# ATSAMD21G17L register map
Vendor: Microchip Technology Inc.; File version: G
CPU: CM0+ r0p1, little endian, no MPU, no FPU, 0x2 interrupt priority bits, 0x0 interrupts
Registers are 32-bit, read-write, reset 0x0 unless marked. A register's access mark holds for its fields unless they carry their own. Offsets are from the block's base; [hi:lo] are bit positions; {n}, {i} and the like mark numbered series; 'fields as' and 'values as' point back to an identical list.

## TCC0 — Timer Counter Control 0
Base 0x42002000; register names take the prefix TCC_
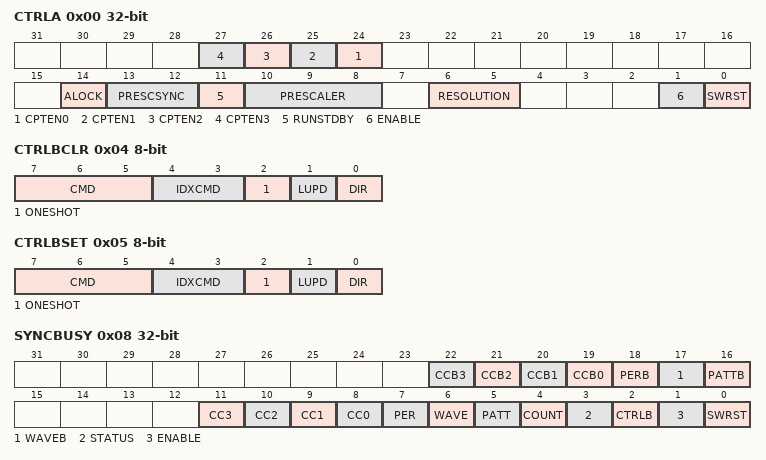
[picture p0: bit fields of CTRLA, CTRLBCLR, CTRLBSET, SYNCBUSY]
0x00 CTRLA — Control A
  [n+24] CPTEN{n} (n=0..3) — Capture Channel {n} Enable
  [14] ALOCK — Auto Lock
  [13:12] PRESCSYNC — Prescaler and Counter Synchronization Selection
    0=GCLK (Reload or reset counter on next GCLK); 1=PRESC (Reload or reset counter on next prescaler clock); 2=RESYNC (Reload or reset counter on next GCLK and reset prescaler counter)
  [11] RUNSTDBY — Run in Standby
  [10:8] PRESCALER
    0=DIV1 (No division); 1=DIV2 (Divide by 2); 2=DIV4 (Divide by 4); 3=DIV8 (Divide by 8); 4=DIV16 (Divide by 16); 5=DIV64 (Divide by 64); 6=DIV256 (Divide by 256); 7=DIV1024 (Divide by 1024)
  [6:5] RESOLUTION — Enhanced Resolution
    0=NONE (Dithering is disabled); 1=DITH4 (Dithering is done every 16 PWM frames); 2=DITH5 (Dithering is done every 32 PWM frames); 3=DITH6 (Dithering is done every 64 PWM frames)
  [1] ENABLE
  [0] SWRST — Software Reset
0x04 CTRLBCLR 8-bit — Control B Clear
  [7:5] CMD — TCC Command
    0=NONE (No action); 1=RETRIGGER (Clear start, restart or retrigger); 2=STOP (Force stop); 3=UPDATE (Force update of double buffered registers); 4=READSYNC (Force COUNT read synchronization)
  [4:3] IDXCMD — Ramp Index Command
    0=DISABLE (Command disabled: Index toggles between cycles A and B); 1=SET (Set index: cycle B will be forced in the next cycle); 2=CLEAR (Clear index: cycle A will be forced in the next cycle); 3=HOLD (Hold index: the next cycle will be the same as the current cycle)
  [2] ONESHOT
  [1] LUPD — Lock Update
  [0] DIR — Counter Direction
0x05 CTRLBSET 8-bit — Control B Set
  fields as CTRLBCLR
0x08 SYNCBUSY ro — Synchronization Busy
  [n+19] CCB{n} (n=0..3) — Compare Channel Buffer {n} Busy
  [18] PERB — Period Buffer Busy
  [17] WAVEB — Wave Buffer Busy
  [16] PATTB — Pattern Buffer Busy
  [n+8] CC{n} (n=0..3) — Compare Channel {n} Busy
  [7] PER — Period busy
  [6] WAVE — Wave Busy
  [5] PATT — Pattern Busy
  [4] COUNT — Count Busy
  [3] STATUS — Status Busy
  [2] CTRLB — Ctrlb Busy
  [1] ENABLE — Enable Busy
  [0] SWRST — Swrst Busy
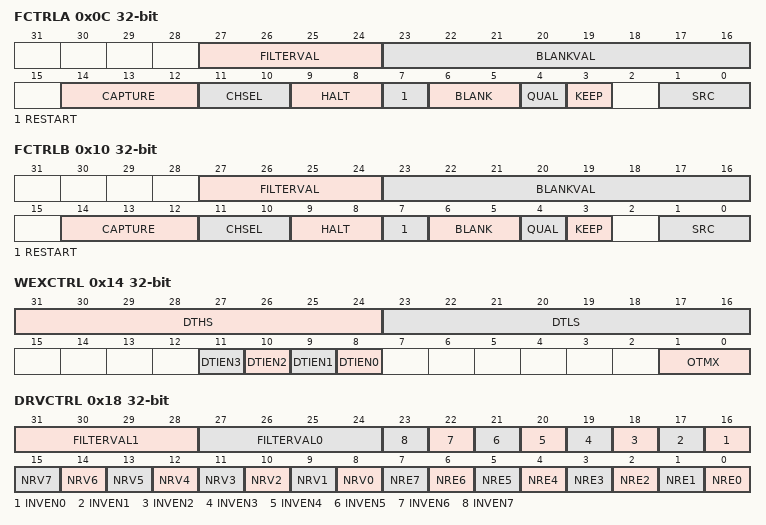
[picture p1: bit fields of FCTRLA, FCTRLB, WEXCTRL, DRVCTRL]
0x0C FCTRLA — Recoverable Fault A Configuration
  [27:24] FILTERVAL — Fault A Filter Value
  [23:16] BLANKVAL — Fault A Blanking Time
  [14:12] CAPTURE — Fault A Capture Action
    0=DISABLE (No capture); 1=CAPT (Capture on fault); 2=CAPTMIN (Minimum capture); 3=CAPTMAX (Maximum capture); 4=LOCMIN (Minimum local detection); 5=LOCMAX (Maximum local detection); 6=DERIV0 (Minimum and maximum local detection); 7=CAPTMARK (Capture with ramp index as MSB value)
  [11:10] CHSEL — Fault A Capture Channel
    {v}=CC{v} (Capture value stored in channel {v}) (v=0..3)
  [9:8] HALT — Fault A Halt Mode
    0=DISABLE (Halt action disabled); 1=HW (Hardware halt action); 2=SW (Software halt action); 3=NR (Non-recoverable fault)
  [7] RESTART — Fault A Restart
  [6:5] BLANK — Fault A Blanking Mode
    0=START (Blanking applied from start of ramp); 1=RISE (Blanking applied from rising edge of the output waveform); 2=FALL (Blanking applied from falling edge of the output waveform); 3=BOTH (Blanking applied from each toggle of the output waveform)
  [4] QUAL — Fault A Qualification
  [3] KEEP — Fault A Keeper
  [1:0] SRC — Fault A Source
    0=DISABLE (Fault input disabled); 1=ENABLE (MCEx (x=0,1) event input); 2=INVERT (Inverted MCEx (x=0,1) event input); 3=ALTFAULT (Alternate fault (A or B) state at the end of the previous period)
0x10 FCTRLB — Recoverable Fault B Configuration
  [27:24] FILTERVAL — Fault B Filter Value
  [23:16] BLANKVAL — Fault B Blanking Time
  [14:12] CAPTURE — Fault B Capture Action
    values as FCTRLA.CAPTURE
  [11:10] CHSEL — Fault B Capture Channel
    {v}=CC{v} (Capture value stored in channel {v}) (v=0..3)
  [9:8] HALT — Fault B Halt Mode
    values as FCTRLA.HALT
  [7] RESTART — Fault B Restart
  [6:5] BLANK — Fault B Blanking Mode
    values as FCTRLA.BLANK
  [4] QUAL — Fault B Qualification
  [3] KEEP — Fault B Keeper
  [1:0] SRC — Fault B Source
    values as FCTRLA.SRC
0x14 WEXCTRL — Waveform Extension Configuration
  [31:24] DTHS — Dead-time High Side Outputs Value
  [23:16] DTLS — Dead-time Low Side Outputs Value
  [n+8] DTIEN{n} (n=0..3) — Dead-time Insertion Generator {n} Enable
  [1:0] OTMX — Output Matrix
0x18 DRVCTRL — Driver Control
  [31:28] FILTERVAL1 — Non-Recoverable Fault Input 1 Filter Value
  [27:24] FILTERVAL0 — Non-Recoverable Fault Input 0 Filter Value
  [n+16] INVEN{n} (n=0..7) — Output Waveform {n} Inversion
  [n+8] NRV{n} (n=0..7) — Non-Recoverable State {n} Output Value
  [n] NRE{n} (n=0..7) — Non-Recoverable State {n} Output Enable
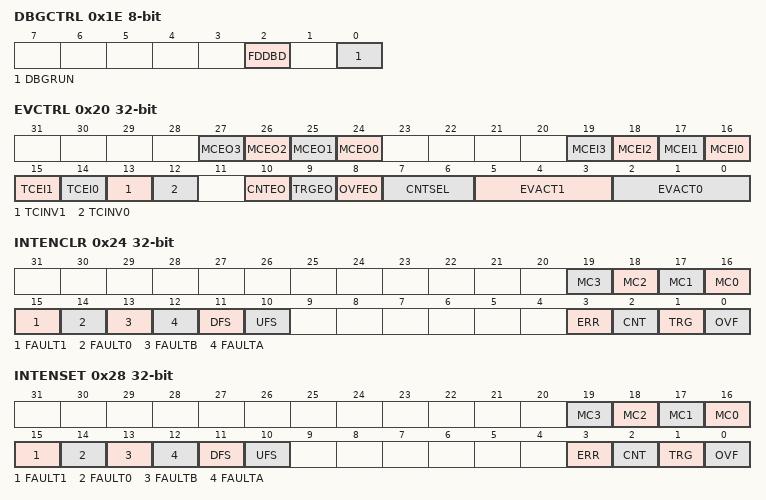
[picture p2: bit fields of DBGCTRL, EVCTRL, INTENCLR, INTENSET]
0x1E DBGCTRL 8-bit — Debug Control
  [2] FDDBD — Fault Detection on Debug Break Detection
  [0] DBGRUN — Debug Running Mode
0x20 EVCTRL — Event Control
  [n+24] MCEO{n} (n=0..3) — Match or Capture Channel {n} Event Output Enable
  [n+16] MCEI{n} (n=0..3) — Match or Capture Channel {n} Event Input Enable
  [15] TCEI1 — Timer/counter Event 1 Input Enable
  [14] TCEI0 — Timer/counter Event 0 Input Enable
  [13] TCINV1 — Inverted Event 1 Input Enable
  [12] TCINV0 — Inverted Event 0 Input Enable
  [10] CNTEO — Timer/counter Output Event Enable
  [9] TRGEO — Retrigger Output Event Enable
  [8] OVFEO — Overflow/Underflow Output Event Enable
  [7:6] CNTSEL — Timer/counter Output Event Mode
    0=START (An interrupt/event is generated when a new counter cycle starts); 1=END (An interrupt/event is generated when a counter cycle ends); 2=BETWEEN (An interrupt/event is generated when a counter cycle ends, except for the first and last cycles); 3=BOUNDARY (An interrupt/event is generated when a new counter cycle starts or a counter cycle ends)
  [5:3] EVACT1 — Timer/counter Input Event1 Action
    0=OFF (Event action disabled); 1=RETRIGGER (Re-trigger counter on event); 2=DIR (Direction control); 3=STOP (Stop counter on event); 4=DEC (Decrement counter on event); 5=PPW (Period capture value in CC0 register, pulse width capture value in CC1 register); 6=PWP (Period capture value in CC1 register, pulse width capture value in CC0 register); 7=FAULT (Non-recoverable fault)
  [2:0] EVACT0 — Timer/counter Input Event0 Action
    0=OFF (Event action disabled); 1=RETRIGGER (Start, restart or re-trigger counter on event); 2=COUNTEV (Count on event); 3=START (Start counter on event); 4=INC (Increment counter on event); 5=COUNT (Count on active state of asynchronous event); 6=STAMP (Stamp capture); 7=FAULT (Non-recoverable fault)
0x24 INTENCLR — Interrupt Enable Clear
  [n+16] MC{n} (n=0..3) — Match or Capture Channel {n} Interrupt Enable
  [15] FAULT1 — Non-Recoverable Fault 1 Interrupt Enable
  [14] FAULT0 — Non-Recoverable Fault 0 Interrupt Enable
  [13] FAULTB — Recoverable Fault B Interrupt Enable
  [12] FAULTA — Recoverable Fault A Interrupt Enable
  [11] DFS — Non-Recoverable Debug Fault Interrupt Enable
  [10] UFS — Non-Recoverable Update Fault Interrupt Enable
  [3] ERR — Error Interrupt Enable
  [2] CNT — Counter Interrupt Enable
  [1] TRG — Retrigger Interrupt Enable
  [0] OVF — Overflow Interrupt Enable
0x28 INTENSET — Interrupt Enable Set
  fields as INTENCLR
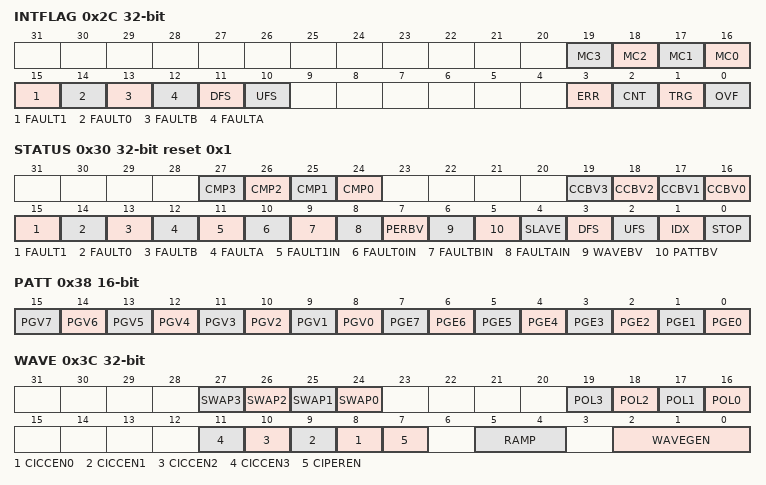
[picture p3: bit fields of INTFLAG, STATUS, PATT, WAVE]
0x2C INTFLAG — Interrupt Flag Status and Clear
  [n+16] MC{n} (n=0..3) — Match or Capture {n}
  [15] FAULT1 — Non-Recoverable Fault 1
  [14] FAULT0 — Non-Recoverable Fault 0
  [13] FAULTB — Recoverable Fault B
  [12] FAULTA — Recoverable Fault A
  [11] DFS — Non-Recoverable Debug Fault
  [10] UFS — Non-Recoverable Update Fault
  [3] ERR — Error
  [2] CNT — Counter
  [1] TRG — Retrigger
  [0] OVF — Overflow
0x30 STATUS reset 0x1
  [n+24] CMP{n} ro (n=0..3) — Compare Channel {n} Value
  [n+16] CCBV{n} (n=0..3) — Compare Channel {n} Buffer Valid
  [15] FAULT1 — Non-Recoverable Fault 1 State
  [14] FAULT0 — Non-Recoverable Fault 0 State
  [13] FAULTB — Recoverable Fault B State
  [12] FAULTA — Recoverable Fault A State
  [11] FAULT1IN ro — Non-Recoverable Fault1 Input
  [10] FAULT0IN ro — Non-Recoverable Fault0 Input
  [9] FAULTBIN ro — Recoverable Fault B Input
  [8] FAULTAIN ro — Recoverable Fault A Input
  [7] PERBV — Period Buffer Valid
  [6] WAVEBV — Wave Buffer Valid
  [5] PATTBV — Pattern Buffer Valid
  [4] SLAVE ro
  [3] DFS — Non-Recoverable Debug Fault State
  [2] UFS — Non-Recoverable Update Fault State
  [1] IDX ro — Ramp
  [0] STOP ro
0x34 COUNT
  [23:0] COUNT — Counter Value
0x34 COUNT_DITH{i} (i=4..6) — Count
  [23:{i}] COUNT — Counter Value
0x38 PATT 16-bit — Pattern
  [n+8] PGV{n} (n=0..7) — Pattern Generator {n} Output Value
  [n] PGE{n} (n=0..7) — Pattern Generator {n} Output Enable
0x3C WAVE — Waveform Control
  [n+24] SWAP{n} (n=0..3) — Swap DTI Output Pair {n}
  [n+16] POL{n} (n=0..3) — Channel {n} Polarity
  [n+8] CICCEN{n} (n=0..3) — Circular Channel {n} Enable
  [7] CIPEREN — Circular period Enable
  [5:4] RAMP — Ramp Mode
    0=RAMP1 operation; 1=RAMP2A (Alternative RAMP2 operation); 2=RAMP2 operation; 3=RAMP2C (Critical RAMP2 operation)
  [2:0] WAVEGEN — Waveform Generation
    0=NFRQ (Normal frequency); 1=MFRQ (Match frequency); 2=NPWM (Normal PWM); 4=DSCRITICAL (Dual-slope critical); 5=DSBOTTOM (Dual-slope with interrupt/event condition when COUNT reaches ZERO); 6=DSBOTH (Dual-slope with interrupt/event condition when COUNT reaches ZERO or TOP); 7=DSTOP (Dual-slope with interrupt/event condition when COUNT reaches TOP)
0x40 PER reset 0xFFFFFFFF — Period
  [23:0] PER — Period Value
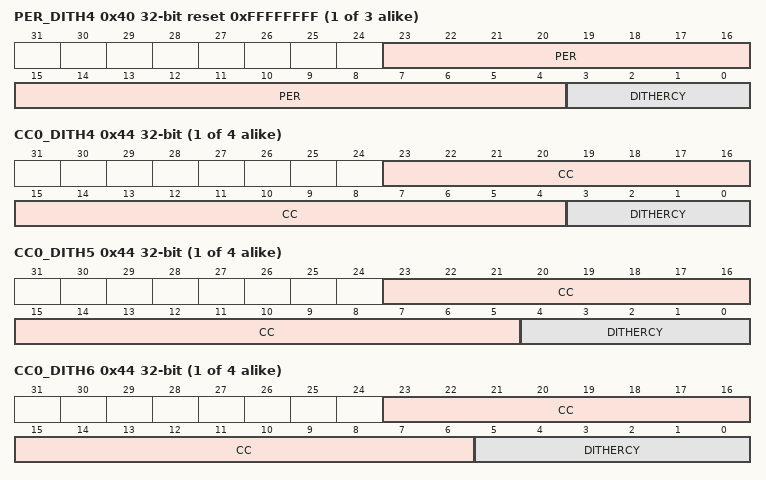
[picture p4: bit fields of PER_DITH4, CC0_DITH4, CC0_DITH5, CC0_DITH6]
0x40 PER_DITH{i} reset 0xFFFFFFFF (i=4..6) — Period
  [23:{i}] PER — Period Value
  [{i-1}:0] DITHERCY — Dithering Cycle Number
{0x44+4i} CC{i} (i=0..3) — Compare and Capture
  [23:0] CC — Channel Compare/Capture Value
{0x44+4i} CC{i}_DITH4 (i=0..3) — Compare and Capture
  [23:4] CC — Channel Compare/Capture Value
  [3:0] DITHERCY — Dithering Cycle Number
{0x44+4i} CC{i}_DITH5 (i=0..3) — Compare and Capture
  [23:5] CC — Channel Compare/Capture Value
  [4:0] DITHERCY — Dithering Cycle Number
{0x44+4i} CC{i}_DITH6 (i=0..3) — Compare and Capture
  [23:6] CC — Channel Compare/Capture Value
  [5:0] DITHERCY — Dithering Cycle Number
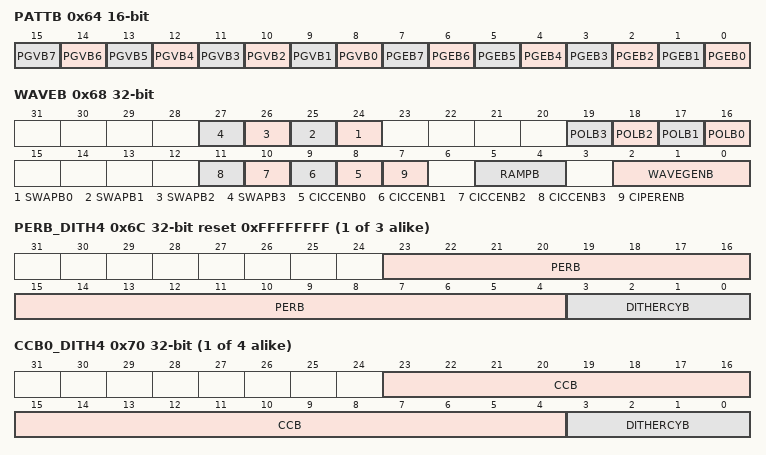
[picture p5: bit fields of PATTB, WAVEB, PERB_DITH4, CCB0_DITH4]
0x64 PATTB 16-bit — Pattern Buffer
  [n+8] PGVB{n} (n=0..7) — Pattern Generator {n} Output Enable
  [n] PGEB{n} (n=0..7) — Pattern Generator {n} Output Enable Buffer
0x68 WAVEB — Waveform Control Buffer
  [n+24] SWAPB{n} (n=0..3) — Swap DTI Output Pair {n} Buffer
  [n+16] POLB{n} (n=0..3) — Channel {n} Polarity Buffer
  [n+8] CICCENB{n} (n=0..3) — Circular Channel {n} Enable Buffer
  [7] CIPERENB — Circular Period Enable Buffer
  [5:4] RAMPB — Ramp Mode Buffer
    0=RAMP1 (RAMP1 operation); 1=RAMP2A (Alternative RAMP2 operation); 2=RAMP2 (RAMP2 operation); 3=RAMP2C (Critical RAMP2 operation)
  [2:0] WAVEGENB — Waveform Generation Buffer
    values as WAVE.WAVEGEN
0x6C PERB reset 0xFFFFFFFF — Period Buffer
  [23:0] PERB — Period Buffer Value
0x6C PERB_DITH{i} reset 0xFFFFFFFF (i=4..6) — Period Buffer
  [23:{i}] PERB — Period Buffer Value
  [{i-1}:0] DITHERCYB — Dithering Buffer Cycle Number
{0x70+4i} CCB{i} (i=0..3) — Compare and Capture Buffer
  [23:0] CCB — Channel Compare/Capture Buffer Value
{0x70+4i} CCB{i}_DITH4 (i=0..3) — Compare and Capture Buffer
  [23:4] CCB — Channel Compare/Capture Buffer Value
  [3:0] DITHERCYB — Dithering Buffer Cycle Number
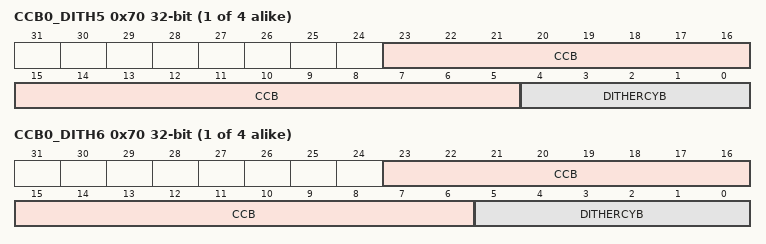
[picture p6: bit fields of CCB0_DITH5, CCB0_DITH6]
{0x70+4i} CCB{i}_DITH5 (i=0..3) — Compare and Capture Buffer
  [23:5] CCB — Channel Compare/Capture Buffer Value
  [4:0] DITHERCYB — Dithering Buffer Cycle Number
{0x70+4i} CCB{i}_DITH6 (i=0..3) — Compare and Capture Buffer
  [23:6] CCB — Channel Compare/Capture Buffer Value
  [5:0] DITHERCYB — Dithering Buffer Cycle Number

## TCC1 — Timer Counter Control 1
Base 0x42002400; register names take the prefix TCC_
Registers as TCC0.

## TCC2 — Timer Counter Control 2
Base 0x42002800; register names take the prefix TCC_
Registers as TCC0.

## TCC3 — Timer Counter Control 3
Base 0x42006000; register names take the prefix TCC_
Registers as TCC0.
